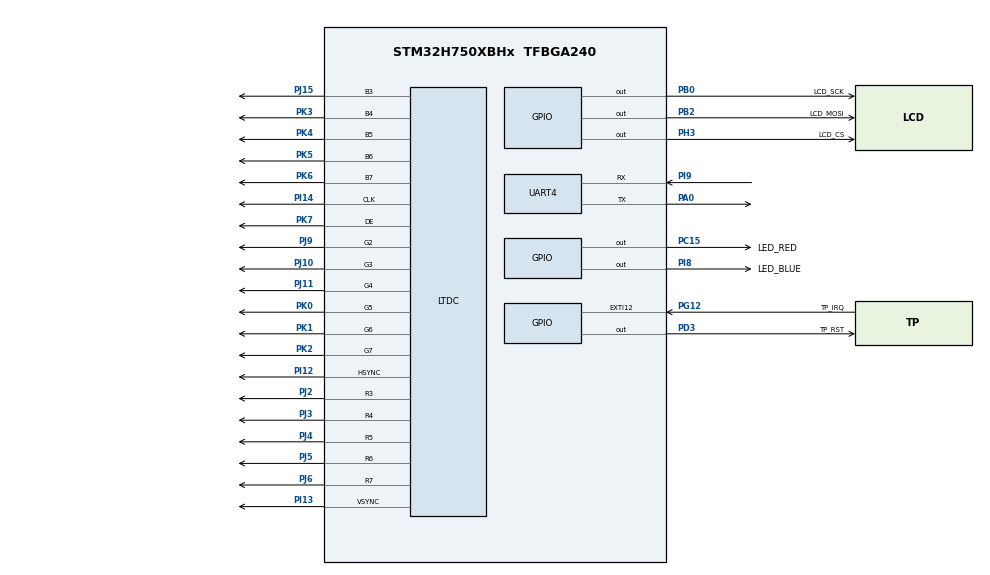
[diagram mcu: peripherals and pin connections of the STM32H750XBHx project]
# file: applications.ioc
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CORTEX_M7.default_mode_Activation=0
FREERTOS.Tasks01=defaultTask,0,128,StartDefaultTask,Default,NULL,Dynamic,NULL,NULL
FREERTOS.configUSE_NEWLIB_REENTRANT=1
Mcu.Family=STM32H7
Mcu.Name=STM32H750XBHx
Mcu.Package=TFBGA240
NVIC.PriorityGroup=NVIC_PRIORITYGROUP_4
NVIC.TIM6_DAC_IRQn=true\:15\:0\:false\:false\:true\:false\:false\:true\:true
NVIC.TimeBase=TIM6_DAC_IRQn
NVIC.TimeBaseIP=TIM6
PA0.Mode=Asynchronous
PA0.PinAttribute=Free
PA0.Signal=UART4_TX
PA13\ (JTMS/SWDIO).Mode=Serial_Wire
PA13\ (JTMS/SWDIO).PinAttribute=Free
PA13\ (JTMS/SWDIO).Signal=DEBUG_JTMS-SWDIO
PA14\ (JTCK/SWCLK).Mode=Serial_Wire
PA14\ (JTCK/SWCLK).PinAttribute=Free
PA14\ (JTCK/SWCLK).Signal=DEBUG_JTCK-SWCLK
PB0.GPIO_Label=LCD_SCK
PB0.GPIO_Speed=GPIO_SPEED_FREQ_LOW
PB0.PinAttribute=Free
PB0.Signal=GPIO_Output
PB2.GPIO_Label=LCD_MOSI
PB2.GPIO_Speed=GPIO_SPEED_FREQ_LOW
PB2.PinAttribute=Free
PB2.Signal=GPIO_Output
PC15-OSC32_OUT\ (OSC32_OUT).GPIO_Label=LED_RED
PC15-OSC32_OUT\ (OSC32_OUT).PinAttribute=Free
PC15-OSC32_OUT\ (OSC32_OUT).PinState=GPIO_PIN_SET
PC15-OSC32_OUT\ (OSC32_OUT).Signal=GPIO_Output
PD3.GPIO_Label=TP_RST
PD3.GPIO_ModeDefaultOutputPP=GPIO_MODE_OUTPUT_OD
PD3.GPIO_PuPd=GPIO_NOPULL
PD3.PinAttribute=Free
PD3.PinState=GPIO_PIN_SET
PD3.Signal=GPIO_Output
PG12.GPIO_Label=TP_IRQ
PG12.PinAttribute=Free
PG12.Signal=SharedStack_PG12
PG12.Stacked=true
PH0-OSC_IN\ (PH0).Mode=HSE-External-Oscillator
PH0-OSC_IN\ (PH0).PinAttribute=Free
PH0-OSC_IN\ (PH0).Signal=RCC_OSC_IN
PH1-OSC_OUT\ (PH1).Mode=HSE-External-Oscillator
PH1-OSC_OUT\ (PH1).PinAttribute=Free
PH1-OSC_OUT\ (PH1).Signal=RCC_OSC_OUT
PH3.GPIO_Label=LCD_CS
PH3.GPIO_Speed=GPIO_SPEED_FREQ_LOW
PH3.PinAttribute=Free
PH3.PinState=GPIO_PIN_SET
PH3.Signal=GPIO_Output
PI12.Mode=RGB565
PI12.PinAttribute=Free
PI12.Signal=LTDC_HSYNC
PI13.Mode=RGB565
PI13.PinAttribute=Free
PI13.Signal=LTDC_VSYNC
PI14.Mode=RGB565
PI14.PinAttribute=Free
PI14.Signal=LTDC_CLK
PI15.PinAttribute=Free
PI15.Signal=LTDC_R0
PI8.GPIO_Label=LED_BLUE
PI8.PinAttribute=Free
PI8.PinState=GPIO_PIN_SET
PI8.Signal=GPIO_Output
PI9.Mode=Asynchronous
PI9.PinAttribute=Free
PI9.Signal=UART4_RX
PJ1.PinAttribute=Free
PJ1.Signal=LTDC_R2
PJ10.Mode=RGB565
PJ10.PinAttribute=Free
PJ10.Signal=LTDC_G3
PJ11.Mode=RGB565
PJ11.PinAttribute=Free
PJ11.Signal=LTDC_G4
PJ14.PinAttribute=Free
PJ14.Signal=LTDC_B2
PJ15.Mode=RGB565
PJ15.PinAttribute=Free
PJ15.Signal=LTDC_B3
PJ2.Mode=RGB565
PJ2.PinAttribute=Free
PJ2.Signal=LTDC_R3
PJ3.Mode=RGB565
PJ3.PinAttribute=Free
PJ3.Signal=LTDC_R4
PJ4.Mode=RGB565
PJ4.PinAttribute=Free
PJ4.Signal=LTDC_R5
PJ5.Mode=RGB565
PJ5.PinAttribute=Free
PJ5.Signal=LTDC_R6
PJ6.Mode=RGB565
PJ6.PinAttribute=Free
PJ6.Signal=LTDC_R7
PJ9.Mode=RGB565
PJ9.PinAttribute=Free
PJ9.Signal=LTDC_G2
PK0.Mode=RGB565
PK0.PinAttribute=Free
PK0.Signal=LTDC_G5
PK1.Mode=RGB565
PK1.PinAttribute=Free
PK1.Signal=LTDC_G6
PK2.Mode=RGB565
PK2.PinAttribute=Free
PK2.Signal=LTDC_G7
PK3.Mode=RGB565
PK3.PinAttribute=Free
PK3.Signal=LTDC_B4
PK4.Mode=RGB565
PK4.PinAttribute=Free
PK4.Signal=LTDC_B5
PK5.Mode=RGB565
PK5.PinAttribute=Free
PK5.Signal=LTDC_B6
PK6.Mode=RGB565
PK6.PinAttribute=Free
PK6.Signal=LTDC_B7
PK7.Mode=RGB565
PK7.PinAttribute=Free
PK7.Signal=LTDC_DE
ProjectManager.HeapSize=0x0
ProjectManager.StackSize=0x1000
ProjectManager.TargetToolchain=STM32CubeIDE
RCC.ADCFreq_Value=400000000
RCC.APB1Freq_Value=120000000
RCC.APB2Freq_Value=120000000
RCC.APB3Freq_Value=120000000
RCC.APB4Freq_Value=120000000
RCC.CortexFreq_Value=480000000
RCC.D1PPRE=RCC_APB3_DIV2
RCC.D2PPRE1=RCC_APB1_DIV2
RCC.D2PPRE2=RCC_APB2_DIV2
RCC.D3PPRE=RCC_APB4_DIV2
RCC.DIVM1=5
RCC.DIVM2=2
RCC.DIVM3=5
RCC.DIVN1=192
RCC.DIVN2=64
RCC.DIVN3=160
RCC.DIVR3=80
RCC.HCLKFreq_Value=240000000
RCC.HPRE=RCC_HCLK_DIV2
RCC.PLL1_VCI_Range-AdvancedSettings=RCC_PLL1VCIRANGE_3
RCC.PLL2_VCI_Range-AdvancedSettings=RCC_PLL2VCIRANGE_3
RCC.PLL2_VCO_SEL-AdvancedSettings=RCC_PLL2VCOMEDIUM
RCC.PLL3_VCI_Range-AdvancedSettings=RCC_PLL3VCIRANGE_0
RCC.PLLFRACN=0
RCC.PLLSourceVirtual=RCC_PLLSOURCE_HSE
RCC.SYSCLKFreq_VALUE=480000000
RCC.SYSCLKSource=RCC_SYSCLKSOURCE_PLLCLK
RCC.USBFreq_Value=480000000
SH.SharedStack_PG12.0=GPIO_EXTI12
UART4.WordLength=WORDLENGTH_8B
VP_FREERTOS_VS_CMSIS_V1.Mode=CMSIS_V1
VP_SYS_VS_tim6.Mode=TIM6
board=custom

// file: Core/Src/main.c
/* USER CODE BEGIN Header */
/**
  ******************************************************************************
  * @file           : main.c
  * @brief          : Main program body
  ******************************************************************************
  * @attention
  *
  * Copyright (c) 2024 STMicroelectronics.
  * All rights reserved.
  *
  * This software is licensed under terms that can be found in the LICENSE file
  * in the root directory of this software component.
  * If no LICENSE file comes with this software, it is provided AS-IS.
  *
  ******************************************************************************
  */
/* USER CODE END Header */
#include "main.h"
#include "cmsis_os.h"

/* USER CODE BEGIN Includes */
#include "stdio.h"

/* USER CODE END Includes */

LTDC_HandleTypeDef hltdc;

UART_HandleTypeDef huart4;

osThreadId defaultTaskHandle;

void SystemClock_Config(void);
static void MX_GPIO_Init(void);
static void MX_UART4_Init(void);
static void MX_LTDC_Init(void);
void StartDefaultTask(void const * argument);

/* USER CODE BEGIN 0 */
int __io_putchar(int ch)
{
  HAL_UART_Transmit(&huart4, (uint8_t *)&ch, 1, 0xFFFF);
  return ch;
}

/* USER CODE END 0 */

int main(void)
{

  /* MCU Configuration--------------------------------------------------------*/

  /* Reset of all peripherals, Initializes the Flash interface and the Systick. */
  HAL_Init();

  /* Configure the system clock */
  SystemClock_Config();

  /* Initialize all configured peripherals */
  MX_GPIO_Init();
  MX_UART4_Init();
  MX_LTDC_Init();

  /* Create the thread(s) */
  /* definition and creation of defaultTask */
  osThreadDef(defaultTask, StartDefaultTask, osPriorityNormal, 0, 128);
  defaultTaskHandle = osThreadCreate(osThread(defaultTask), NULL);

  /* Start scheduler */
  osKernelStart();

  /* We should never get here as control is now taken by the scheduler */
  /* Infinite loop */
  while (1)
  {

  }
}

void SystemClock_Config(void)
{
  RCC_OscInitTypeDef RCC_OscInitStruct = {0};
  RCC_ClkInitTypeDef RCC_ClkInitStruct = {0};

  /** Supply configuration update enable
  */
  HAL_PWREx_ConfigSupply(PWR_LDO_SUPPLY);

  /** Configure the main internal regulator output voltage
  */
  __HAL_PWR_VOLTAGESCALING_CONFIG(PWR_REGULATOR_VOLTAGE_SCALE1);

  while(!__HAL_PWR_GET_FLAG(PWR_FLAG_VOSRDY)) {}

  __HAL_RCC_SYSCFG_CLK_ENABLE();
  __HAL_PWR_VOLTAGESCALING_CONFIG(PWR_REGULATOR_VOLTAGE_SCALE0);

  while(!__HAL_PWR_GET_FLAG(PWR_FLAG_VOSRDY)) {}

  /** Initializes the RCC Oscillators according to the specified parameters
  * in the RCC_OscInitTypeDef structure.
  */
  RCC_OscInitStruct.OscillatorType = RCC_OSCILLATORTYPE_HSE;
  RCC_OscInitStruct.HSEState = RCC_HSE_ON;
  RCC_OscInitStruct.PLL.PLLState = RCC_PLL_ON;
  RCC_OscInitStruct.PLL.PLLSource = RCC_PLLSOURCE_HSE;
  RCC_OscInitStruct.PLL.PLLM = 5;
  RCC_OscInitStruct.PLL.PLLN = 192;
  RCC_OscInitStruct.PLL.PLLP = 2;
  RCC_OscInitStruct.PLL.PLLQ = 2;
  RCC_OscInitStruct.PLL.PLLR = 2;
  RCC_OscInitStruct.PLL.PLLRGE = RCC_PLL1VCIRANGE_2;
  RCC_OscInitStruct.PLL.PLLVCOSEL = RCC_PLL1VCOWIDE;
  RCC_OscInitStruct.PLL.PLLFRACN = 0;
  if (HAL_RCC_OscConfig(&RCC_OscInitStruct) != HAL_OK)
  {
    Error_Handler();
  }

  /** Initializes the CPU, AHB and APB buses clocks
  */
  RCC_ClkInitStruct.ClockType = RCC_CLOCKTYPE_HCLK|RCC_CLOCKTYPE_SYSCLK
                              |RCC_CLOCKTYPE_PCLK1|RCC_CLOCKTYPE_PCLK2
                              |RCC_CLOCKTYPE_D3PCLK1|RCC_CLOCKTYPE_D1PCLK1;
  RCC_ClkInitStruct.SYSCLKSource = RCC_SYSCLKSOURCE_PLLCLK;
  RCC_ClkInitStruct.SYSCLKDivider = RCC_SYSCLK_DIV1;
  RCC_ClkInitStruct.AHBCLKDivider = RCC_HCLK_DIV2;
  RCC_ClkInitStruct.APB3CLKDivider = RCC_APB3_DIV2;
  RCC_ClkInitStruct.APB1CLKDivider = RCC_APB1_DIV2;
  RCC_ClkInitStruct.APB2CLKDivider = RCC_APB2_DIV2;
  RCC_ClkInitStruct.APB4CLKDivider = RCC_APB4_DIV2;

  if (HAL_RCC_ClockConfig(&RCC_ClkInitStruct, FLASH_LATENCY_4) != HAL_OK)
  {
    Error_Handler();
  }
}

static void MX_LTDC_Init(void)
{

  LTDC_LayerCfgTypeDef pLayerCfg = {0};
  LTDC_LayerCfgTypeDef pLayerCfg1 = {0};

  hltdc.Instance = LTDC;
  hltdc.Init.HSPolarity = LTDC_HSPOLARITY_AL;
  hltdc.Init.VSPolarity = LTDC_VSPOLARITY_AL;
  hltdc.Init.DEPolarity = LTDC_DEPOLARITY_AL;
  hltdc.Init.PCPolarity = LTDC_PCPOLARITY_IPC;
  hltdc.Init.HorizontalSync = 7;
  hltdc.Init.VerticalSync = 3;
  hltdc.Init.AccumulatedHBP = 14;
  hltdc.Init.AccumulatedVBP = 5;
  hltdc.Init.AccumulatedActiveW = 654;
  hltdc.Init.AccumulatedActiveH = 485;
  hltdc.Init.TotalWidth = 660;
  hltdc.Init.TotalHeigh = 487;
  hltdc.Init.Backcolor.Blue = 0;
  hltdc.Init.Backcolor.Green = 0;
  hltdc.Init.Backcolor.Red = 0;
  if (HAL_LTDC_Init(&hltdc) != HAL_OK)
  {
    Error_Handler();
  }
  pLayerCfg.WindowX0 = 0;
  pLayerCfg.WindowX1 = 0;
  pLayerCfg.WindowY0 = 0;
  pLayerCfg.WindowY1 = 0;
  pLayerCfg.PixelFormat = LTDC_PIXEL_FORMAT_ARGB8888;
  pLayerCfg.Alpha = 0;
  pLayerCfg.Alpha0 = 0;
  pLayerCfg.BlendingFactor1 = LTDC_BLENDING_FACTOR1_CA;
  pLayerCfg.BlendingFactor2 = LTDC_BLENDING_FACTOR2_CA;
  pLayerCfg.FBStartAdress = 0;
  pLayerCfg.ImageWidth = 0;
  pLayerCfg.ImageHeight = 0;
  pLayerCfg.Backcolor.Blue = 0;
  pLayerCfg.Backcolor.Green = 0;
  pLayerCfg.Backcolor.Red = 0;
  if (HAL_LTDC_ConfigLayer(&hltdc, &pLayerCfg, 0) != HAL_OK)
  {
    Error_Handler();
  }
  pLayerCfg1.WindowX0 = 0;
  pLayerCfg1.WindowX1 = 0;
  pLayerCfg1.WindowY0 = 0;
  pLayerCfg1.WindowY1 = 0;
  pLayerCfg1.PixelFormat = LTDC_PIXEL_FORMAT_ARGB8888;
  pLayerCfg1.Alpha = 0;
  pLayerCfg1.Alpha0 = 0;
  pLayerCfg1.BlendingFactor1 = LTDC_BLENDING_FACTOR1_CA;
  pLayerCfg1.BlendingFactor2 = LTDC_BLENDING_FACTOR2_CA;
  pLayerCfg1.FBStartAdress = 0;
  pLayerCfg1.ImageWidth = 0;
  pLayerCfg1.ImageHeight = 0;
  pLayerCfg1.Backcolor.Blue = 0;
  pLayerCfg1.Backcolor.Green = 0;
  pLayerCfg1.Backcolor.Red = 0;
  if (HAL_LTDC_ConfigLayer(&hltdc, &pLayerCfg1, 1) != HAL_OK)
  {
    Error_Handler();
  }

}

static void MX_UART4_Init(void)
{

  huart4.Instance = UART4;
  huart4.Init.BaudRate = 115200;
  huart4.Init.WordLength = UART_WORDLENGTH_8B;
  huart4.Init.StopBits = UART_STOPBITS_1;
  huart4.Init.Parity = UART_PARITY_NONE;
  huart4.Init.Mode = UART_MODE_TX_RX;
  huart4.Init.HwFlowCtl = UART_HWCONTROL_NONE;
  huart4.Init.OverSampling = UART_OVERSAMPLING_16;
  huart4.Init.OneBitSampling = UART_ONE_BIT_SAMPLE_DISABLE;
  huart4.Init.ClockPrescaler = UART_PRESCALER_DIV1;
  huart4.AdvancedInit.AdvFeatureInit = UART_ADVFEATURE_NO_INIT;
  if (HAL_UART_Init(&huart4) != HAL_OK)
  {
    Error_Handler();
  }
  if (HAL_UARTEx_SetTxFifoThreshold(&huart4, UART_TXFIFO_THRESHOLD_1_8) != HAL_OK)
  {
    Error_Handler();
  }
  if (HAL_UARTEx_SetRxFifoThreshold(&huart4, UART_RXFIFO_THRESHOLD_1_8) != HAL_OK)
  {
    Error_Handler();
  }
  if (HAL_UARTEx_DisableFifoMode(&huart4) != HAL_OK)
  {
    Error_Handler();
  }

}

static void MX_GPIO_Init(void)
{
  GPIO_InitTypeDef GPIO_InitStruct = {0};

  /* GPIO Ports Clock Enable */
  __HAL_RCC_GPIOK_CLK_ENABLE();
  __HAL_RCC_GPIOJ_CLK_ENABLE();
  __HAL_RCC_GPIOD_CLK_ENABLE();
  __HAL_RCC_GPIOA_CLK_ENABLE();
  __HAL_RCC_GPIOC_CLK_ENABLE();
  __HAL_RCC_GPIOG_CLK_ENABLE();
  __HAL_RCC_GPIOI_CLK_ENABLE();
  __HAL_RCC_GPIOH_CLK_ENABLE();
  __HAL_RCC_GPIOB_CLK_ENABLE();

  /*Configure GPIO pin Output Level */
  HAL_GPIO_WritePin(TP_RST_GPIO_Port, TP_RST_Pin, GPIO_PIN_SET);

  /*Configure GPIO pin Output Level */
  HAL_GPIO_WritePin(LED_RED_GPIO_Port, LED_RED_Pin, GPIO_PIN_SET);

  /*Configure GPIO pin Output Level */
  HAL_GPIO_WritePin(LED_BLUE_GPIO_Port, LED_BLUE_Pin, GPIO_PIN_SET);

  /*Configure GPIO pin Output Level */
  HAL_GPIO_WritePin(LCD_CS_GPIO_Port, LCD_CS_Pin, GPIO_PIN_SET);

  /*Configure GPIO pin Output Level */
  HAL_GPIO_WritePin(GPIOB, LCD_MOSI_Pin|LCD_SCK_Pin, GPIO_PIN_RESET);

  /*Configure GPIO pin : TP_RST_Pin */
  GPIO_InitStruct.Pin = TP_RST_Pin;
  GPIO_InitStruct.Mode = GPIO_MODE_OUTPUT_OD;
  GPIO_InitStruct.Pull = GPIO_NOPULL;
  GPIO_InitStruct.Speed = GPIO_SPEED_FREQ_LOW;
  HAL_GPIO_Init(TP_RST_GPIO_Port, &GPIO_InitStruct);

  /*Configure GPIO pin : LED_RED_Pin */
  GPIO_InitStruct.Pin = LED_RED_Pin;
  GPIO_InitStruct.Mode = GPIO_MODE_OUTPUT_PP;
  GPIO_InitStruct.Pull = GPIO_NOPULL;
  GPIO_InitStruct.Speed = GPIO_SPEED_FREQ_LOW;
  HAL_GPIO_Init(LED_RED_GPIO_Port, &GPIO_InitStruct);

  /*Configure GPIO pin : TP_IRQ_Pin */
  GPIO_InitStruct.Pin = TP_IRQ_Pin;
  GPIO_InitStruct.Mode = GPIO_MODE_IT_RISING;
  GPIO_InitStruct.Pull = GPIO_NOPULL;
  HAL_GPIO_Init(TP_IRQ_GPIO_Port, &GPIO_InitStruct);

  /*Configure GPIO pin : LED_BLUE_Pin */
  GPIO_InitStruct.Pin = LED_BLUE_Pin;
  GPIO_InitStruct.Mode = GPIO_MODE_OUTPUT_PP;
  GPIO_InitStruct.Pull = GPIO_NOPULL;
  GPIO_InitStruct.Speed = GPIO_SPEED_FREQ_LOW;
  HAL_GPIO_Init(LED_BLUE_GPIO_Port, &GPIO_InitStruct);

  /*Configure GPIO pin : LCD_CS_Pin */
  GPIO_InitStruct.Pin = LCD_CS_Pin;
  GPIO_InitStruct.Mode = GPIO_MODE_OUTPUT_PP;
  GPIO_InitStruct.Pull = GPIO_NOPULL;
  GPIO_InitStruct.Speed = GPIO_SPEED_FREQ_LOW;
  HAL_GPIO_Init(LCD_CS_GPIO_Port, &GPIO_InitStruct);

  /*Configure GPIO pins : LCD_MOSI_Pin LCD_SCK_Pin */
  GPIO_InitStruct.Pin = LCD_MOSI_Pin|LCD_SCK_Pin;
  GPIO_InitStruct.Mode = GPIO_MODE_OUTPUT_PP;
  GPIO_InitStruct.Pull = GPIO_NOPULL;
  GPIO_InitStruct.Speed = GPIO_SPEED_FREQ_LOW;
  HAL_GPIO_Init(GPIOB, &GPIO_InitStruct);

}

void StartDefaultTask(void const * argument)
{
  /* USER CODE BEGIN 5 */
  /* Infinite loop */
  for(;;)
  {
    printf("[info applications]Hello World!\r\n");
    osDelay(1000);
    HAL_GPIO_TogglePin(LED_RED_GPIO_Port, LED_RED_Pin);
  }
  /* USER CODE END 5 */
}

void HAL_TIM_PeriodElapsedCallback(TIM_HandleTypeDef *htim)
{
  if (htim->Instance == TIM6) {
    HAL_IncTick();
  }
}

void Error_Handler(void)
{
  __disable_irq();
  while (1)
  {
  }
}
